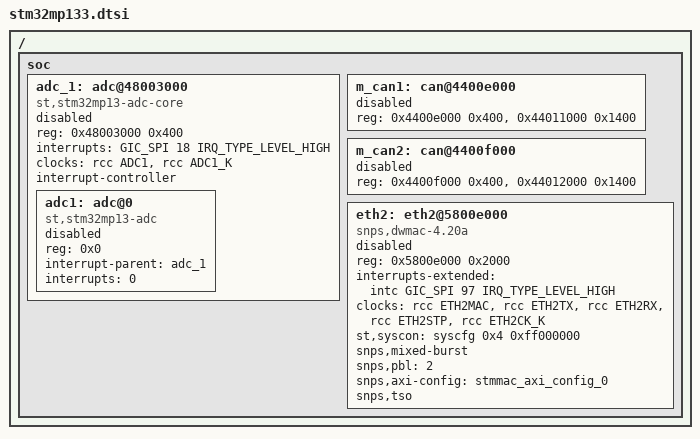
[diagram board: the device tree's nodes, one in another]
// SPDX-License-Identifier: (GPL-2.0+ OR BSD-3-Clause)
/*
 * Copyright (C) STMicroelectronics 2019 - All Rights Reserved
 * Author: Alexandre Torgue <alexandre.torgue@st.com> for STMicroelectronics.
 */

#include "stm32mp131.dtsi"

/ {
	soc {
		adc_1: adc@48003000 {
			compatible = "st,stm32mp13-adc-core";
			reg = <0x48003000 0x400>;
			interrupts = <GIC_SPI 18 IRQ_TYPE_LEVEL_HIGH>;
			clocks = <&rcc ADC1>, <&rcc ADC1_K>;
			clock-names = "bus", "adc";
			interrupt-controller;
			#interrupt-cells = <1>;
			#address-cells = <1>;
			#size-cells = <0>;
			status = "disabled";

			adc1: adc@0 {
				compatible = "st,stm32mp13-adc";
				#io-channel-cells = <1>;
				reg = <0x0>;
				interrupt-parent = <&adc_1>;
				interrupts = <0>;
				status = "disabled";
			};
		};

		m_can1: can@4400e000 {
			reg = <0x4400e000 0x400>, <0x44011000 0x1400>;
			status = "disabled";
		};

		m_can2: can@4400f000 {
			reg = <0x4400f000 0x400>, <0x44012000 0x1400>;
			status = "disabled";
		};

		eth2: eth2@5800e000 {
			compatible = "snps,dwmac-4.20a", "st,stm32mp13-dwmac";
			reg = <0x5800e000 0x2000>;
			reg-names = "stmmaceth";
			interrupts-extended = <&intc GIC_SPI 97 IRQ_TYPE_LEVEL_HIGH>;
			interrupt-names = "macirq";
			clock-names = "stmmaceth",
				      "mac-clk-tx",
				      "mac-clk-rx",
				      "ethstp",
				      "eth-ck";
			clocks = <&rcc ETH2MAC>,
				 <&rcc ETH2TX>,
				 <&rcc ETH2RX>,
				 <&rcc ETH2STP>,
				 <&rcc ETH2CK_K>;
			st,syscon = <&syscfg 0x4 0xff000000>;
			snps,mixed-burst;
			snps,pbl = <2>;
			snps,axi-config = <&stmmac_axi_config_0>;
			snps,tso;
			status = "disabled";
		};
	};
};
